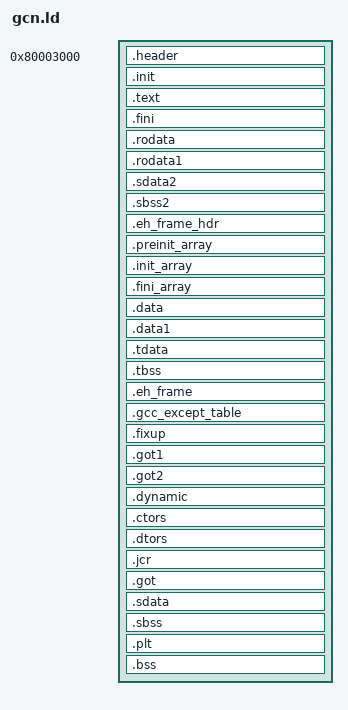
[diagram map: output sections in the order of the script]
/* Default linker script, for normal executables */
OUTPUT_FORMAT("elf32-powerpc", "elf32-powerpc",
	      "elf32-powerpc")
OUTPUT_ARCH(powerpc:common)
ENTRY(_start)
PROVIDE (__stack = 0x817F0000);
SECTIONS
{

  /* DOL header (from TITANIK's GC docs)
   */
  . = 0x80003000;

  .header	:
  {
  	file_start = .;
	/*    0000-001B  Text[0..6] sections File Positions */
	LONG(text_file_start);
	LONG(0);
	LONG(0);
	LONG(0);
	LONG(0);
	LONG(0);
	LONG(0);

	/*    001C-0047  Data[0..10] sections File Positions */
	LONG(data_file_start);
	LONG(0);
	LONG(0);
	LONG(0);
	LONG(0);
	LONG(0);
	LONG(0);
	LONG(0);
	LONG(0);
	LONG(0);
	LONG(0);

	/*    0048-0063  Text[0..6] sections Mem Address */
	LONG(text_mem_start);
	LONG(0);
	LONG(0);
	LONG(0);
	LONG(0);
	LONG(0);
	LONG(0);

	/*    0064-008F  Data[0..10] sections Mem Address */
	LONG(data_mem_start);
	LONG(0);
	LONG(0);
	LONG(0);
	LONG(0);
	LONG(0);
	LONG(0);
	LONG(0);
	LONG(0);
	LONG(0);
	LONG(0);

	/*    0090-00AB  Text[0..6] sections Sizes */
	LONG(text_mem_size);
	LONG(0);
	LONG(0);
	LONG(0);
	LONG(0);
	LONG(0);
	LONG(0);

	/*    00AC-00D7  Data[0..10] sections Sizes */
	LONG(data_mem_size);
	LONG(0);
	LONG(0);
	LONG(0);
	LONG(0);
	LONG(0);
	LONG(0);
	LONG(0);
	LONG(0);
	LONG(0);
	LONG(0);

	/*    00D8  BSS Mem address
	 *    00DC  BSS Size */
	LONG(bss_mem_start);
	LONG(bss_mem_size);

	/*    00E0  Entry Point */
	LONG(ABSOLUTE(_start));
  }


  . = file_start + 0x100;

  text_mem_start = .;

  .init           :
  {
    KEEP (*(.init))
  } =0
  /* Read-only sections, merged into text segment: */
/*  .interp         : { *(.interp) }
  .hash           : { *(.hash) }
  .dynsym         : { *(.dynsym) }
  .dynstr         : { *(.dynstr) }
  .gnu.version    : { *(.gnu.version) }
  .gnu.version_d  : { *(.gnu.version_d) }
  .gnu.version_r  : { *(.gnu.version_r) }
  .rel.init       : { *(.rel.init) }
  .rela.init      : { *(.rela.init) }
  .rel.text       : { *(.rel.text .rel.text.* .rel.gnu.linkonce.t.*) }
  .rela.text      : { *(.rela.text .rela.text.* .rela.gnu.linkonce.t.*) }
  .rel.fini       : { *(.rel.fini) }
  .rela.fini      : { *(.rela.fini) }
  .rel.rodata     : { *(.rel.rodata .rel.rodata.* .rel.gnu.linkonce.r.*) }
  .rela.rodata    : { *(.rela.rodata .rela.rodata.* .rela.gnu.linkonce.r.*) }
  .rel.data       : { *(.rel.data .rel.data.* .rel.gnu.linkonce.d.*) }
  .rela.data      : { *(.rela.data .rela.data.* .rela.gnu.linkonce.d.*) }
  .rel.tdata	  : { *(.rel.tdata .rel.tdata.* .rel.gnu.linkonce.td.*) }
  .rela.tdata	  : { *(.rela.tdata .rela.tdata.* .rela.gnu.linkonce.td.*) }
  .rel.tbss	  : { *(.rel.tbss .rel.tbss.* .rel.gnu.linkonce.tb.*) }
  .rela.tbss	  : { *(.rela.tbss .rela.tbss.* .rela.gnu.linkonce.tb.*) }
  .rel.ctors      : { *(.rel.ctors) }
  .rela.ctors     : { *(.rela.ctors) }
  .rel.dtors      : { *(.rel.dtors) }
  .rela.dtors     : { *(.rela.dtors) }
  .rel.got        : { *(.rel.got) }
  .rela.got       : { *(.rela.got) }
  .rela.got1           : { *(.rela.got1) }
  .rela.got2           : { *(.rela.got2) }
  .rel.sdata      : { *(.rel.sdata .rel.sdata.* .rel.gnu.linkonce.s.*) }
  .rela.sdata     : { *(.rela.sdata .rela.sdata.* .rela.gnu.linkonce.s.*) }
  .rel.sbss       : { *(.rel.sbss .rel.sbss.* .rel.gnu.linkonce.sb.*) }
  .rela.sbss      : { *(.rela.sbss .rela.sbss.* .rela.gnu.linkonce.sb.*) }
  .rel.sdata2     : { *(.rel.sdata2 .rel.sdata2.* .rel.gnu.linkonce.s2.*) }
  .rela.sdata2    : { *(.rela.sdata2 .rela.sdata2.* .rela.gnu.linkonce.s2.*) }
  .rel.sbss2      : { *(.rel.sbss2 .rel.sbss2.* .rel.gnu.linkonce.sb2.*) }
  .rela.sbss2     : { *(.rela.sbss2 .rela.sbss2.* .rela.gnu.linkonce.sb2.*) }
  .rel.bss        : { *(.rel.bss .rel.bss.* .rel.gnu.linkonce.b.*) }
  .rela.bss       : { *(.rela.bss .rela.bss.* .rela.gnu.linkonce.b.*) }
  .rel.plt        : { *(.rel.plt) }
  .rela.plt       : { *(.rela.plt) }
*/
  .text           :
  {
    *(.text .stub .text.* .gnu.linkonce.t.*)
    /* .gnu.warning sections are handled specially by elf32.em.  */
    *(.gnu.warning)
  } =0
  .fini           :
  {
    KEEP (*(.fini))
  } =0
  PROVIDE (__etext = .);
  PROVIDE (_etext = .);
  PROVIDE (etext = .);
  . = ALIGN(32);
 text_mem_size = . - text_mem_start;
  data_mem_start = .;
   .rodata         : { *(.rodata .rodata.* .gnu.linkonce.r.*) }
  .rodata1        : { *(.rodata1) }
  .sdata2         : { *(.sdata2 .sdata2.* .gnu.linkonce.s2.*) }
  .sbss2          : { *(.sbss2 .sbss2.* .gnu.linkonce.sb2.*) }
  .eh_frame_hdr : { *(.eh_frame_hdr) }
  . = ALIGN(32);
  /* Ensure the __preinit_array_start label is properly aligned.  We
     could instead move the label definition inside the section, but
     the linker would then create the section even if it turns out to
     be empty, which isn't pretty.  */
  . = ALIGN(32 / 8);
  PROVIDE (__preinit_array_start = .);
  .preinit_array     : { *(.preinit_array) }
  PROVIDE (__preinit_array_end = .);
  PROVIDE (__init_array_start = .);
  .init_array     : { *(.init_array) }
  PROVIDE (__init_array_end = .);
  PROVIDE (__fini_array_start = .);
  .fini_array     : { *(.fini_array) }
  PROVIDE (__fini_array_end = .);
  .data           :
  {
    *(.data .data.* .gnu.linkonce.d.*)
    SORT(CONSTRUCTORS)
  }
  .data1          : { *(.data1) }
  .tdata	  : { *(.tdata .tdata.* .gnu.linkonce.td.*) }
  .tbss		  : { *(.tbss .tbss.* .gnu.linkonce.tb.*) *(.tcommon) }
  .eh_frame       : { KEEP (*(.eh_frame)) }
  .gcc_except_table   : { *(.gcc_except_table) }
  .fixup          : { *(.fixup) }
  .got1           : { *(.got1) }
  .got2           : { *(.got2) }
  .dynamic        : { *(.dynamic) }
  .ctors          :
  {
    /* gcc uses crtbegin.o to find the start of
       the constructors, so we make sure it is
       first.  Because this is a wildcard, it
       doesn't matter if the user does not
       actually link against crtbegin.o; the
       linker won't look for a file to match a
       wildcard.  The wildcard also means that it
       doesn't matter which directory crtbegin.o
       is in.  */
    KEEP (*crtbegin*.o(.ctors))
    /* We don't want to include the .ctor section from
       from the crtend.o file until after the sorted ctors.
       The .ctor section from the crtend file contains the
       end of ctors marker and it must be last */
    KEEP (*(EXCLUDE_FILE (*crtend*.o ) .ctors))
    KEEP (*(SORT(.ctors.*)))
    KEEP (*(.ctors))
  }
  .dtors          :
  {
    KEEP (*crtbegin*.o(.dtors))
    KEEP (*(EXCLUDE_FILE (*crtend*.o ) .dtors))
    KEEP (*(SORT(.dtors.*)))
    KEEP (*(.dtors))
  }
  .jcr            : { KEEP (*(.jcr)) }
  .got            : { *(.got.plt) *(.got) }
  /* We want the small data sections together, so single-instruction offsets
     can access them all, and initialized data all before uninitialized, so
     we can shorten the on-disk segment size.  */
  .sdata          :
  {
    *(.sdata .sdata.* .gnu.linkonce.s.*)
  }
  _edata = .;
  PROVIDE (edata = .);

data_mem_size = . - data_mem_start;
  bss_mem_start = .;

  __bss_start = .;
  .sbss           :
  {
    PROVIDE (__sbss_start = .);
    PROVIDE (___sbss_start = .);
    *(.dynsbss)
    *(.sbss .sbss.* .gnu.linkonce.sb.*)
    *(.scommon)
    PROVIDE (__sbss_end = .);
    PROVIDE (___sbss_end = .);
  }
  .plt            : { *(.plt) }
  .bss            :
  {
   *(.dynbss)
   *(.bss .bss.* .gnu.linkonce.b.*)
   *(COMMON)
   /* Align here to ensure that the .bss section occupies space up to
      _end.  Align after .bss to ensure correct alignment even if the
      .bss section disappears because there are no input sections.  */
   . = ALIGN(32 / 8);
  }
  . = ALIGN(32 / 8);
 bss_mem_size = . - bss_mem_start;
text_file_start = text_mem_start - file_start;
data_file_start = data_mem_start - file_start;


  _end = .;
  __end = .;
  PROVIDE (end = .);

  /* Discard anything not explicitly mentioned above */
  /DISCARD/ : { *(*); }
}
